AUTOSAR XML (schema 4-0-3)
standard types defined: Boolean, UInt16, UInt32, UInt8
package /AUTOSAR_Platform/DataConstrs
  range DC_Boolean: raw 0..1
  range DC_UInt16: raw 0..65535
  range DC_UInt8: raw 0..255
package /PATAC/MSM/ComponentTypes
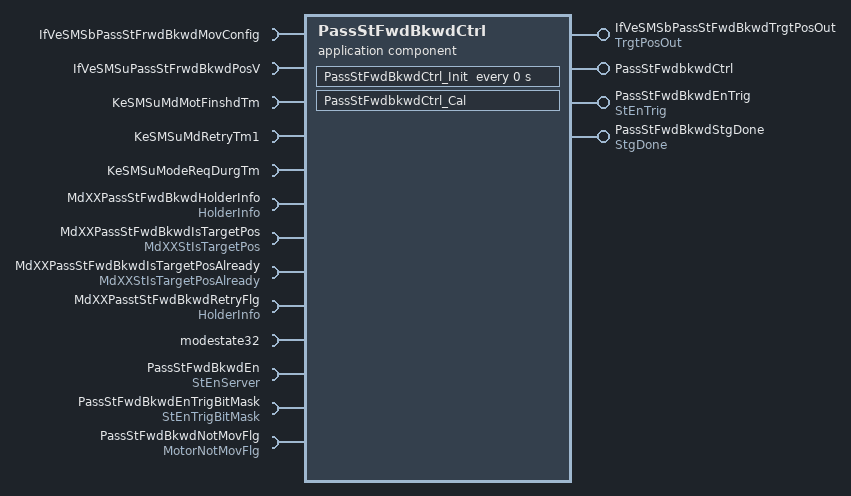
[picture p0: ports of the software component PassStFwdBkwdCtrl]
  application sw component type PassStFwdBkwdCtrl
    4 x provide port:
      IfVeSMSbPassStFwdBkwdTrgtPosOut: nonqueued-sender-com-spec{data-element=TrgtPosOut/Val, init-value=0}, provided-interface=TrgtPosOut
      PassStFwdbkwdCtrl: server-com-spec{operation=Cal, queue-length=1}, provided-interface=PassStFwdbkwdCtrl
      PassStFwdBkwdEnTrig: nonqueued-sender-com-spec{data-element=StEnTrig/Val, init-value=0}, provided-interface=StEnTrig
      PassStFwdBkwdStgDone: nonqueued-sender-com-spec{data-element=StgDone/Val, init-value=0}, provided-interface=StgDone
    13 x require port:
      IfVeSMSbPassStFrwdBkwdMovConfig: nonqueued-receiver-com-spec{data-element=IfVeSMSbPassStFrwdBkwdMovConfig/Val, filter=data-filter-type=ALWAYS, init-value=0}, required-interface=IfVeSMSbPassStFrwdBkwdMovConfig
      IfVeSMSuPassStFrwdBkwdPosV: nonqueued-receiver-com-spec{data-element=IfVeSMSuPassStFrwdBkwdPosV/Val, filter=data-filter-type=ALWAYS, init-value=0}, required-interface=IfVeSMSuPassStFrwdBkwdPosV
      KeSMSuMdMotFinshdTm: parameter-require-com-spec{init-value=0, parameter=KeSMSuMdMotFinshdTm/Val}, required-interface=KeSMSuMdMotFinshdTm
      KeSMSuMdRetryTm1: parameter-require-com-spec{init-value=0, parameter=KeSMSuMdRetryTm1/Val}, required-interface=KeSMSuMdRetryTm1
      KeSMSuModeReqDurgTm: parameter-require-com-spec{init-value=0, parameter=KeSMSuModeReqDurgTm/Val}, required-interface=KeSMSuModeReqDurgTm
      MdXXPassStFwdBkwdHolderInfo: nonqueued-receiver-com-spec{data-element=HolderInfo/Val, filter=data-filter-type=ALWAYS, init-value=0}, required-interface=HolderInfo
      MdXXPassStFwdBkwdIsTargetPos: nonqueued-receiver-com-spec{data-element=MdXXStIsTargetPos/Val, filter=data-filter-type=ALWAYS, init-value=0}, required-interface=MdXXStIsTargetPos
      MdXXPassStFwdBkwdIsTargetPosAlready: nonqueued-receiver-com-spec{data-element=MdXXStIsTargetPosAlready/Val, filter=data-filter-type=ALWAYS, init-value=0}, required-interface=MdXXStIsTargetPosAlready
      MdXXPasstStFwdBkwdRetryFlg: nonqueued-receiver-com-spec{data-element=HolderInfo/Val, filter=data-filter-type=ALWAYS, init-value=0}, required-interface=HolderInfo
      modestate32: nonqueued-receiver-com-spec{data-element=modestate32/Val, filter=data-filter-type=ALWAYS, init-value=0}, required-interface=modestate32
      PassStFwdBkwdEn: required-com-specs=[Clear, Get, Set], required-interface=StEnServer
      PassStFwdBkwdEnTrigBitMask: nonqueued-receiver-com-spec{data-element=StEnTrigBitMask/Val, filter=data-filter-type=ALWAYS, init-value=0}, required-interface=StEnTrigBitMask
      PassStFwdBkwdNotMovFlg: nonqueued-receiver-com-spec{data-element=MotorNotMovFlg/Val, filter=data-filter-type=ALWAYS, init-value=0}, required-interface=MotorNotMovFlg
    behavior PassStFwdBkwdCtrl_InternalBehavior
      operation invoked event OIT_PassStFwdbkwdCtrl_Cal_PassStFwdbkwdCtrl_Cal: start-on-event=PassStFwdbkwdCtrl_Cal, operation=PassStFwdbkwdCtrl.Cal
      timing event PassStFwdBkwdCtrl_InitEvent: start-on-event=PassStFwdBkwdCtrl_Init, period=0
      runnable PassStFwdbkwdCtrl_Cal
        data-receive-point-by-arguments:
          9 x access:
            REC_IfVeSMSbPassStFrwdBkwdMovConfig_Val: accessed-variable=IfVeSMSbPassStFrwdBkwdMovConfig.Val
            REC_IfVeSMSuPassStFrwdBkwdPosV_Val: accessed-variable=IfVeSMSuPassStFrwdBkwdPosV.Val
            REC_MdXXPassStFwdBkwdHolderInfo_Val: accessed-variable=MdXXPassStFwdBkwdHolderInfo.Val
            REC_MdXXPassStFwdBkwdIsTargetPos_Val: accessed-variable=MdXXPassStFwdBkwdIsTargetPos.Val
            REC_MdXXPassStFwdBkwdIsTargetPosAlready_Val: accessed-variable=MdXXPassStFwdBkwdIsTargetPosAlready.Val
            REC_MdXXPasstStFwdBkwdRetryFlg_Val: accessed-variable=MdXXPasstStFwdBkwdRetryFlg.Val
            REC_modestate32_Val: accessed-variable=modestate32.Val
            REC_PassStFwdBkwdEnTrigBitMask_Val: accessed-variable=PassStFwdBkwdEnTrigBitMask.Val
            REC_PassStFwdBkwdNotMovFlg_Val: accessed-variable=PassStFwdBkwdNotMovFlg.Val
        data-send-points:
          access SEND_IfVeSMSbPassStFwdBkwdTrgtPosOut_Val: accessed-variable=IfVeSMSbPassStFwdBkwdTrgtPosOut.Val
          access SEND_PassStFwdBkwdEnTrig_Val: accessed-variable=PassStFwdBkwdEnTrig.Val
          access SEND_PassStFwdBkwdStgDone_Val: accessed-variable=PassStFwdBkwdStgDone.Val
        parameter access PA_KeSMSuMdMotFinshdTm_Val: accessed-parameter=KeSMSuMdMotFinshdTm.Val
        parameter access PA_KeSMSuMdRetryTm1_Val: accessed-parameter=KeSMSuMdRetryTm1.Val
        parameter access PA_KeSMSuModeReqDurgTm_Val: accessed-parameter=KeSMSuModeReqDurgTm.Val
        sync call SC_PassStFwdBkwdEn_Get: operation=PassStFwdBkwdEn.Get, timeout=0
      runnable PassStFwdBkwdCtrl_Init
        parameter access PA_KeSMSuMdMotFinshdTm_Val: accessed-parameter=KeSMSuMdMotFinshdTm.Val
        parameter access PA_KeSMSuMdRetryTm1_Val: accessed-parameter=KeSMSuMdRetryTm1.Val
        parameter access PA_KeSMSuModeReqDurgTm_Val: accessed-parameter=KeSMSuModeReqDurgTm.Val
  swc implementation PassStFwdBkwdCtrl_Implementation: behavior=PassStFwdBkwdCtrl_InternalBehavior
    code-descriptors:
      code Default: artifact-descriptors=autosar-engineering-object={short-label=Default, category=SWSRC}
package /PATAC/MSM/ModeAdjust/CalPortInterface
  parameter interface KeSMSuMdMotFinshdTm
    parameter data prototype Val: sw-calibration-access=READ-WRITE, type=UInt16
  parameter interface KeSMSuModeReqDurgTm
    parameter data prototype Val: sw-calibration-access=READ-WRITE, type=UInt16
package /PATAC/MSM/ModeAdjust/Interfaces
  sender receiver interface IfVeSMSuPassStFrwdBkwdPosV: invalidation-policy{data-element=IfVeSMSuPassStFrwdBkwdPosV/Val, handle-invalid=DONT-INVALIDATE}
    data Val: type=Boolean
package /PATAC/MSM/ModeAdjust/PortInterface
  client server interface PassStFwdbkwdCtrl
    operation Cal
  client server interface StEnServer
    operation Clear
      arg data: type=UInt8, direction=IN, server-argument-impl-policy=USE-ARGUMENT-TYPE
    operation Get
      arg data: type=UInt32, direction=OUT, server-argument-impl-policy=USE-ARGUMENT-TYPE
    operation Set
      arg data: type=UInt8, direction=IN, server-argument-impl-policy=USE-ARGUMENT-TYPE
  9 x sender receiver interface:
    HolderInfo: invalidation-policy{data-element=HolderInfo/Val, handle-invalid=DONT-INVALIDATE}
      data Val: type=UInt32
    MdXXStIsTargetPos: invalidation-policy{data-element=MdXXStIsTargetPos/Val, handle-invalid=DONT-INVALIDATE}
      data Val: type=UInt32
    MdXXStIsTargetPosAlready: invalidation-policy{data-element=MdXXStIsTargetPosAlready/Val, handle-invalid=DONT-INVALIDATE}
      data Val: type=UInt32
    modestate32: invalidation-policy{data-element=modestate32/Val, handle-invalid=DONT-INVALIDATE}
      data Val: type=UInt32
    MotorNotMovFlg: invalidation-policy{data-element=MotorNotMovFlg/Val, handle-invalid=DONT-INVALIDATE}
      data Val: type=Boolean
    StEnTrig: invalidation-policy{data-element=StEnTrig/Val, handle-invalid=DONT-INVALIDATE}
      data Val: type=Boolean
    StEnTrigBitMask: invalidation-policy{data-element=StEnTrigBitMask/Val, handle-invalid=DONT-INVALIDATE}
      data Val: type=UInt32
    StgDone: invalidation-policy{data-element=StgDone/Val, handle-invalid=DONT-INVALIDATE}
      data Val: type=Boolean
    TrgtPosOut: invalidation-policy{data-element=TrgtPosOut/Val, handle-invalid=DONT-INVALIDATE}
      data Val: type=Boolean
package /PATAC/MSM/PortInterfaces
  parameter interface KeSMSuMdRetryTm1
    parameter data prototype Val: sw-calibration-access=READ-WRITE, type=UInt8
  sender receiver interface IfVeSMSbPassStFrwdBkwdMovConfig: invalidation-policy{data-element=IfVeSMSbPassStFrwdBkwdMovConfig/Val, handle-invalid=DONT-INVALIDATE}
    data Val: type=Boolean
